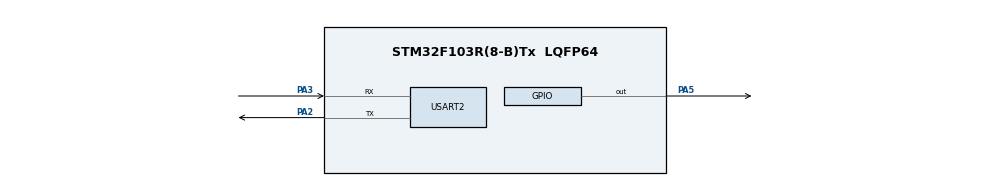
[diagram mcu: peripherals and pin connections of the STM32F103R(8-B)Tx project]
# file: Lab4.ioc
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Mcu.Family=STM32F1
Mcu.Name=STM32F103R(8-B)Tx
Mcu.Package=LQFP64
NVIC.PriorityGroup=NVIC_PRIORITYGROUP_4
PA13.Mode=Serial_Wire
PA13.Signal=SYS_JTMS-SWDIO
PA14.Mode=Serial_Wire
PA14.Signal=SYS_JTCK-SWCLK
PA2.Mode=Asynchronous
PA2.Signal=USART2_TX
PA3.Mode=Asynchronous
PA3.Signal=USART2_RX
PA5.Signal=GPIO_Output
ProjectManager.HeapSize=0x200
ProjectManager.StackSize=0x400
ProjectManager.TargetToolchain=STM32CubeIDE
RCC.APB1Freq_Value=8000000
RCC.APB2Freq_Value=8000000
TIM4.CounterMode=TIM_COUNTERMODE_DOWN
TIM4.Prescaler=0
USART2.VirtualMode=VM_ASYNC
VP_TIM4_VS_ClockSourceINT.Mode=Internal
board=custom

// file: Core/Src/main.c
/* USER CODE BEGIN Header */
/**
  ******************************************************************************
  * @file           : main.c
  * @brief          : Main program body
  ******************************************************************************
  * @attention
  *
  * <h2><center>&copy; Copyright (c) 2020 STMicroelectronics.
  * All rights reserved.</center></h2>
  *
  * This software component is licensed by ST under BSD 3-Clause license,
  * the "License"; You may not use this file except in compliance with the
  * License. You may obtain a copy of the License at:
  *                        opensource.org/licenses/BSD-3-Clause
  *
  ******************************************************************************
  */
/* USER CODE END Header */
#include "main.h"

/* USER CODE BEGIN Includes */
#include "timer.h"
#include "cli.h"
/* USER CODE END Includes */

TIM_HandleTypeDef htim4;

UART_HandleTypeDef huart2;

void SystemClock_Config(void);
static void MX_GPIO_Init(void);
static void MX_TIM4_Init(void);
static void MX_USART2_UART_Init(void);

int main(void)
{

  /* MCU Configuration--------------------------------------------------------*/

  /* Reset of all peripherals, Initializes the Flash interface and the Systick. */
  HAL_Init();

  /* Configure the system clock */
  SystemClock_Config();

  /* Initialize all configured peripherals */
  MX_GPIO_Init();
  MX_TIM4_Init();
  MX_USART2_UART_Init();
  /* USER CODE BEGIN 2 */
  HAL_TIM_Base_Start(&htim4);	//tim4 starts counting
  reset_buffer();
  display_intro(huart2);
  reset_buffer();
  /* USER CODE END 2 */

  /* Infinite loop */
  /* USER CODE BEGIN WHILE */
  while (1)
  {
	  display_prompt(huart2);
	  getCommand(huart2);
	  displayCommand(huart2, htim4);

    /* USER CODE END WHILE */

  }
}

void SystemClock_Config(void)
{
  RCC_OscInitTypeDef RCC_OscInitStruct = {0};
  RCC_ClkInitTypeDef RCC_ClkInitStruct = {0};

  /** Initializes the RCC Oscillators according to the specified parameters
  * in the RCC_OscInitTypeDef structure.
  */
  RCC_OscInitStruct.OscillatorType = RCC_OSCILLATORTYPE_HSI;
  RCC_OscInitStruct.HSIState = RCC_HSI_ON;
  RCC_OscInitStruct.HSICalibrationValue = RCC_HSICALIBRATION_DEFAULT;
  RCC_OscInitStruct.PLL.PLLState = RCC_PLL_NONE;
  if (HAL_RCC_OscConfig(&RCC_OscInitStruct) != HAL_OK)
  {
    Error_Handler();
  }
  /** Initializes the CPU, AHB and APB buses clocks
  */
  RCC_ClkInitStruct.ClockType = RCC_CLOCKTYPE_HCLK|RCC_CLOCKTYPE_SYSCLK
                              |RCC_CLOCKTYPE_PCLK1|RCC_CLOCKTYPE_PCLK2;
  RCC_ClkInitStruct.SYSCLKSource = RCC_SYSCLKSOURCE_HSI;
  RCC_ClkInitStruct.AHBCLKDivider = RCC_SYSCLK_DIV1;
  RCC_ClkInitStruct.APB1CLKDivider = RCC_HCLK_DIV1;
  RCC_ClkInitStruct.APB2CLKDivider = RCC_HCLK_DIV1;

  if (HAL_RCC_ClockConfig(&RCC_ClkInitStruct, FLASH_LATENCY_0) != HAL_OK)
  {
    Error_Handler();
  }
}

static void MX_TIM4_Init(void)
{

  TIM_ClockConfigTypeDef sClockSourceConfig = {0};
  TIM_MasterConfigTypeDef sMasterConfig = {0};

  htim4.Instance = TIM4;
  htim4.Init.Prescaler = 0;
  htim4.Init.CounterMode = TIM_COUNTERMODE_DOWN;
  htim4.Init.Period = 65535;
  htim4.Init.ClockDivision = TIM_CLOCKDIVISION_DIV1;
  htim4.Init.AutoReloadPreload = TIM_AUTORELOAD_PRELOAD_DISABLE;
  if (HAL_TIM_Base_Init(&htim4) != HAL_OK)
  {
    Error_Handler();
  }
  sClockSourceConfig.ClockSource = TIM_CLOCKSOURCE_INTERNAL;
  if (HAL_TIM_ConfigClockSource(&htim4, &sClockSourceConfig) != HAL_OK)
  {
    Error_Handler();
  }
  sMasterConfig.MasterOutputTrigger = TIM_TRGO_RESET;
  sMasterConfig.MasterSlaveMode = TIM_MASTERSLAVEMODE_DISABLE;
  if (HAL_TIMEx_MasterConfigSynchronization(&htim4, &sMasterConfig) != HAL_OK)
  {
    Error_Handler();
  }

}

static void MX_USART2_UART_Init(void)
{

  huart2.Instance = USART2;
  huart2.Init.BaudRate = 115200;
  huart2.Init.WordLength = UART_WORDLENGTH_8B;
  huart2.Init.StopBits = UART_STOPBITS_1;
  huart2.Init.Parity = UART_PARITY_NONE;
  huart2.Init.Mode = UART_MODE_TX_RX;
  huart2.Init.HwFlowCtl = UART_HWCONTROL_NONE;
  huart2.Init.OverSampling = UART_OVERSAMPLING_16;
  if (HAL_UART_Init(&huart2) != HAL_OK)
  {
    Error_Handler();
  }

}

static void MX_GPIO_Init(void)
{
  GPIO_InitTypeDef GPIO_InitStruct = {0};

  /* GPIO Ports Clock Enable */
  __HAL_RCC_GPIOA_CLK_ENABLE();

  /*Configure GPIO pin Output Level */
  HAL_GPIO_WritePin(GPIOA, GPIO_PIN_5, GPIO_PIN_RESET);

  /*Configure GPIO pin : PA5 */
  GPIO_InitStruct.Pin = GPIO_PIN_5;
  GPIO_InitStruct.Mode = GPIO_MODE_OUTPUT_PP;
  GPIO_InitStruct.Pull = GPIO_NOPULL;
  GPIO_InitStruct.Speed = GPIO_SPEED_FREQ_LOW;
  HAL_GPIO_Init(GPIOA, &GPIO_InitStruct);

}

void Error_Handler(void)
{
}

/************************ (C) COPYRIGHT STMicroelectronics *****END OF FILE****/
